# iosam3n register map
Registers are 32-bit, access not given, no defined reset value unless marked. A register's access mark holds for its fields unless they carry their own. Addresses are absolute; registers are grouped by the start of their names; [hi:lo] are bit positions; {n}, {i} and the like mark numbered series; 'fields as' and 'values as' point back to an identical list.

## SCB
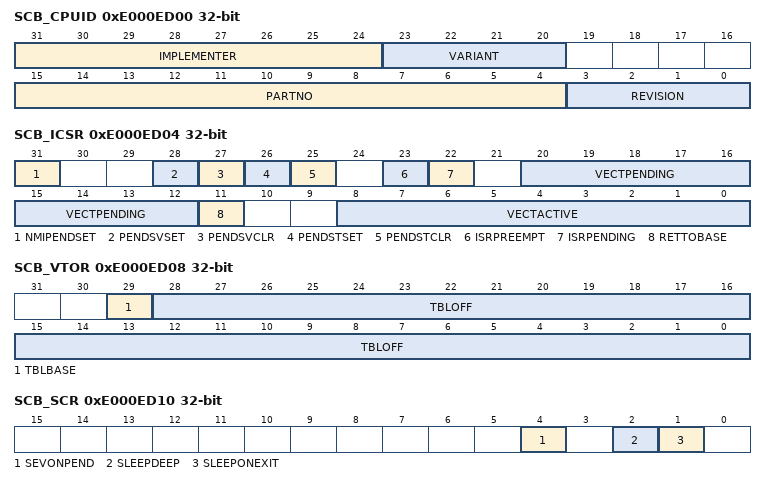
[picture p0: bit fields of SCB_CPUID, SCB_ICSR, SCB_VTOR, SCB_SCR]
0xE000ED00 SCB_CPUID
  [31:24] IMPLEMENTER, [23:20] VARIANT, [15:4] PARTNO, [3:0] REVISION
0xE000ED04 SCB_ICSR
  [31] NMIPENDSET, [28] PENDSVSET, [27] PENDSVCLR, [26] PENDSTSET, [25] PENDSTCLR, [23] ISRPREEMPT, [22] ISRPENDING, [20:12] VECTPENDING, [11] RETTOBASE, [8:0] VECTACTIVE
0xE000ED08 SCB_VTOR
  [29] TBLBASE, [28:0] TBLOFF
0xE000ED0C SCB_AIRCR
  [31:16] VECTKEY, [31:16] VECTKEYSTAT, [15] ENDIANESS, [2] SYSRESETREQ, [1] VECTCLRACTIVE, [0] VECTRESET
0xE000ED10 SCB_SCR
  [4] SEVONPEND, [2] SLEEPDEEP, [1] SLEEPONEXIT
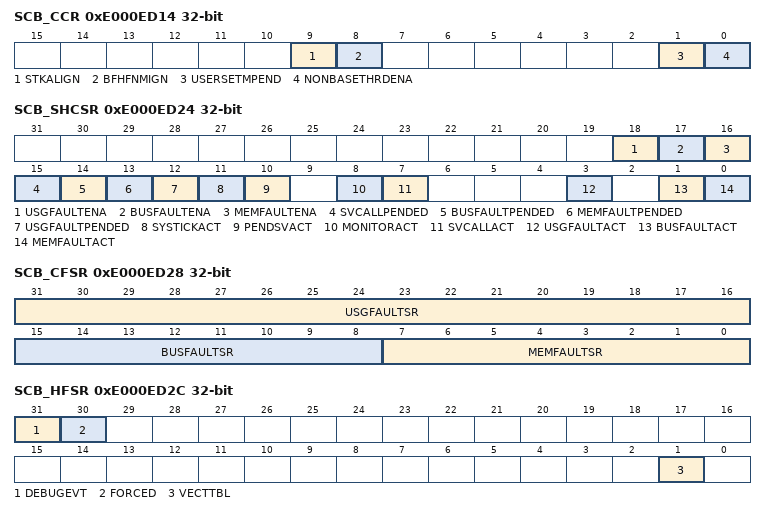
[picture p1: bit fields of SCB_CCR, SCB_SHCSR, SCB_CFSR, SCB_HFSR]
0xE000ED14 SCB_CCR
  [9] STKALIGN, [8] BFHFNMIGN, [1] USERSETMPEND, [0] NONBASETHRDENA
{0xE000ED18+4i} SCB_SHP{i} 8-bit (i=0..11)
0xE000ED24 SCB_SHCSR
  [18] USGFAULTENA, [17] BUSFAULTENA, [16] MEMFAULTENA, [15] SVCALLPENDED, [14] BUSFAULTPENDED, [13] MEMFAULTPENDED, [12] USGFAULTPENDED, [11] SYSTICKACT, [10] PENDSVACT, [8] MONITORACT, [7] SVCALLACT, [3] USGFAULTACT, [1] BUSFAULTACT, [0] MEMFAULTACT
0xE000ED28 SCB_CFSR
  [31:16] USGFAULTSR, [15:8] BUSFAULTSR, [7:0] MEMFAULTSR
0xE000ED2C SCB_HFSR
  [31] DEBUGEVT, [30] FORCED, [1] VECTTBL
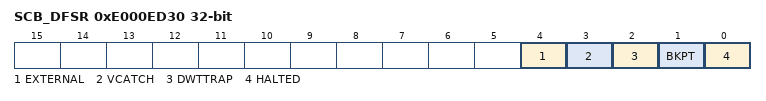
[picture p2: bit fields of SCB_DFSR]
0xE000ED30 SCB_DFSR
  [4] EXTERNAL, [3] VCATCH, [2] DWTTRAP, [1] BKPT, [0] HALTED
0xE000ED34 SCB_MMFAR
0xE000ED38 SCB_BFAR
0xE000ED3C SCB_AFSR
0xE000ED40 SCB_PFR0
0xE000ED44 SCB_PFR1
0xE000ED48 SCB_DFR
0xE000ED4C SCB_ADR
{0xE000ED50+4i} SCB_MMFR{i} (i=0..3)
{0xE000ED60+4i} SCB_ISAR{i} (i=0..4)

## SYSTICK
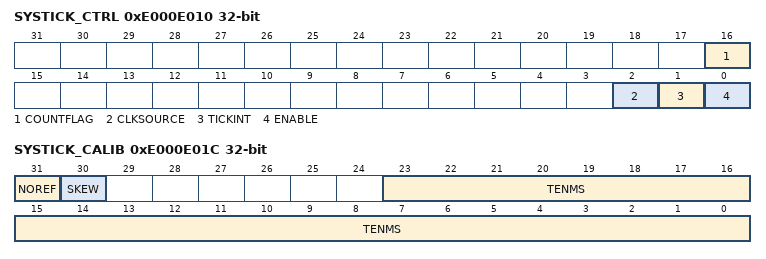
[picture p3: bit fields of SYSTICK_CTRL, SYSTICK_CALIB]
0xE000E010 SYSTICK_CTRL
  [16] COUNTFLAG, [2] CLKSOURCE, [1] TICKINT, [0] ENABLE
0xE000E014 SYSTICK_LOAD
  [23:0] RELOAD
0xE000E018 SYSTICK_VAL
  [23:0] CURRENT
0xE000E01C SYSTICK_CALIB
  [31] NOREF, [30] SKEW, [23:0] TENMS

## INTERRUPTTYPE
0xE000E004 INTERRUPTTYPE_ICTR
  [4:0] INTLINESNUM
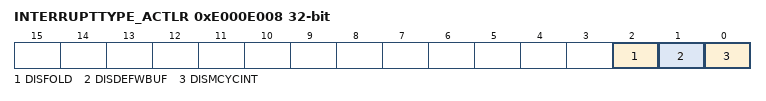
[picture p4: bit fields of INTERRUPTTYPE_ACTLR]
0xE000E008 INTERRUPTTYPE_ACTLR
  [2] DISFOLD, [1] DISDEFWBUF, [0] DISMCYCINT

## COREDEBUG
0xE000EDF0 COREDEBUG_DHCSR
  [31:16] DBGKEY
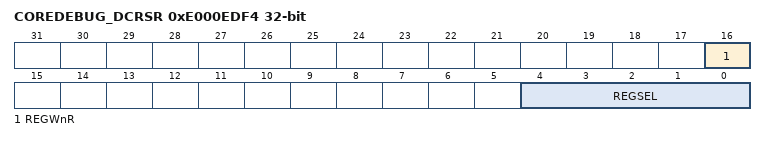
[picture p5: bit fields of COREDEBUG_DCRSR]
0xE000EDF4 COREDEBUG_DCRSR
  [16] REGWnR, [4:0] REGSEL
0xE000EDF8 COREDEBUG_DCRDR
0xE000EDFC COREDEBUG_DEMCR
  [24] TRCENA

## SPI
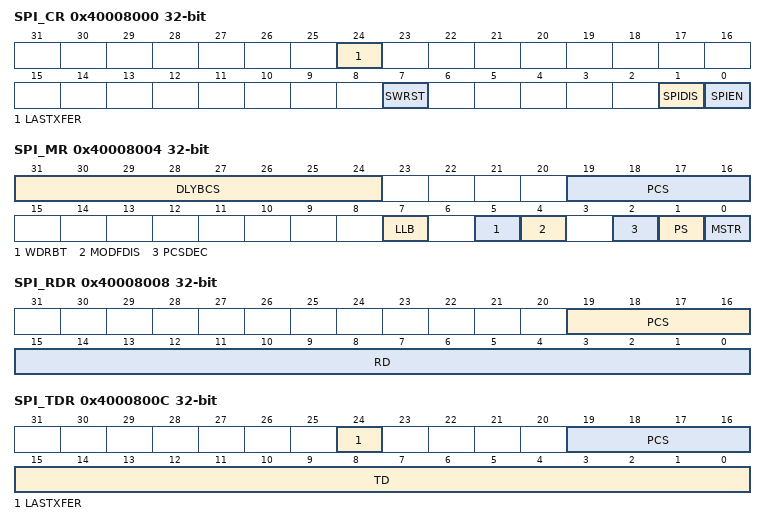
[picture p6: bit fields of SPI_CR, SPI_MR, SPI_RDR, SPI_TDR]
0x40008000 SPI_CR
  [24] LASTXFER, [7] SWRST, [1] SPIDIS, [0] SPIEN
0x40008004 SPI_MR
  [31:24] DLYBCS, [19:16] PCS, [7] LLB, [5] WDRBT, [4] MODFDIS, [2] PCSDEC, [1] PS, [0] MSTR
0x40008008 SPI_RDR
  [19:16] PCS, [15:0] RD
0x4000800C SPI_TDR
  [24] LASTXFER, [19:16] PCS, [15:0] TD
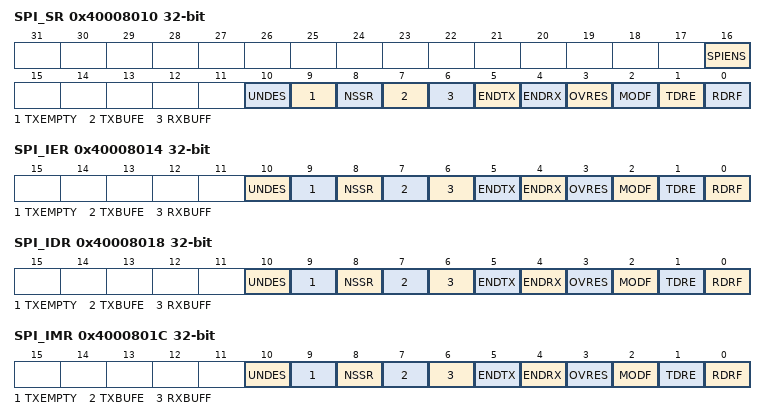
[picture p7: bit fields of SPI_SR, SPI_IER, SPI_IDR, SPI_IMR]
0x40008010 SPI_SR
  [16] SPIENS, [10] UNDES, [9] TXEMPTY, [8] NSSR, [7] TXBUFE, [6] RXBUFF, [5] ENDTX, [4] ENDRX, [3] OVRES, [2] MODF, [1] TDRE, [0] RDRF
0x40008014 SPI_IER
  [10] UNDES, [9] TXEMPTY, [8] NSSR, [7] TXBUFE, [6] RXBUFF, [5] ENDTX, [4] ENDRX, [3] OVRES, [2] MODF, [1] TDRE, [0] RDRF
0x40008018 SPI_IDR
  fields as SPI_IER
0x4000801C SPI_IMR
  fields as SPI_IER
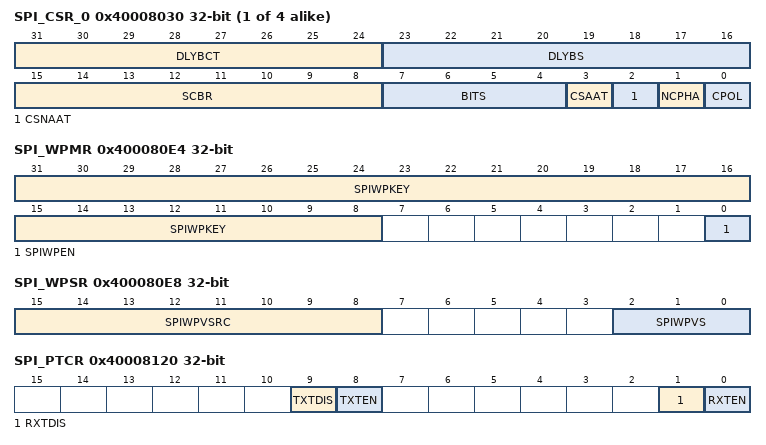
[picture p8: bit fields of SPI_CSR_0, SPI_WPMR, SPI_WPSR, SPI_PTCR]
{0x40008030+4i} SPI_CSR_{i} (i=0..3)
  [31:24] DLYBCT, [23:16] DLYBS, [15:8] SCBR, [7:4] BITS, [3] CSAAT, [2] CSNAAT, [1] NCPHA, [0] CPOL
0x400080E4 SPI_WPMR
  [31:8] SPIWPKEY, [0] SPIWPEN
0x400080E8 SPI_WPSR
  [15:8] SPIWPVSRC, [2:0] SPIWPVS
0x40008100 SPI_RPR
  [31:0] RXPTR
0x40008104 SPI_RCR
  [15:0] RXCTR
0x40008108 SPI_TPR
  [31:0] TXPTR
0x4000810C SPI_TCR
  [15:0] TXCTR
0x40008110 SPI_RNPR
  [31:0] RXNPTR
0x40008114 SPI_RNCR
  [15:0] RXNCTR
0x40008118 SPI_TNPR
  [31:0] TXNPTR
0x4000811C SPI_TNCR
  [15:0] TXNCTR
0x40008120 SPI_PTCR
  [9] TXTDIS, [8] TXTEN, [1] RXTDIS, [0] RXTEN
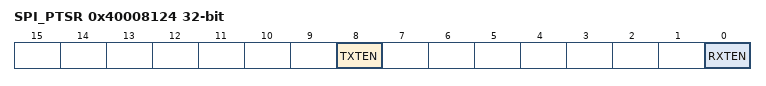
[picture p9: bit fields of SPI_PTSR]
0x40008124 SPI_PTSR
  [8] TXTEN, [0] RXTEN

## TC0
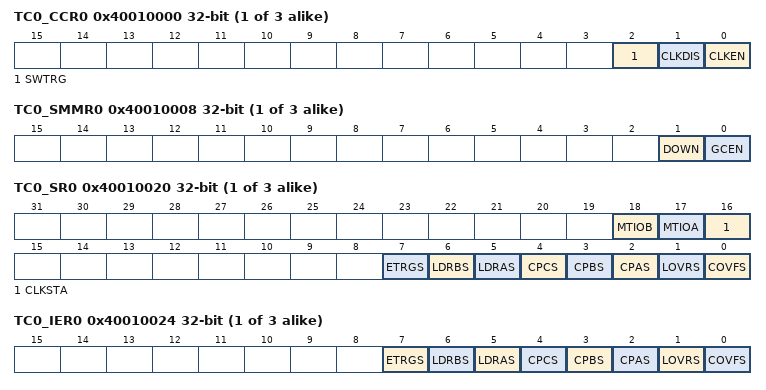
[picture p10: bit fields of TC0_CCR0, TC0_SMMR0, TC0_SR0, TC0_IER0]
{0x40010000+0x40*i} TC0_CCR{i} (i=0..2)
  [2] SWTRG, [1] CLKDIS, [0] CLKEN
{0x40010004+0x40*i} TC0_CMR{i} (i=0..2)
  [31:30] BSWTRG, [29:28] BEEVT, [27:26] BCPC, [25:24] BCPB, [23:22] ASWTRG, [21:20] AEEVT, [19:18] LDRB, [19:18] ACPC, [17:16] LDRA, [17:16] ACPA, [15] WAVE, [14] CPCTRG, [14:13] WAVSEL, [12] ENETRG, [10] ABETRG, [11:10] EEVT, [9:8] ETRGEDG, [9:8] EEVTEDG, [7] LDBDIS, [7] CPCDIS, [6] LDBSTOP, [6] CPCSTOP, [5:4] BURST, [3] CLKI, [2:0] TCCLKS
{0x40010008+0x40*i} TC0_SMMR{i} (i=0..2)
  [1] DOWN, [0] GCEN
{0x40010010+0x40*i} TC0_CV{i} (i=0..2)
  [15:0] CV
{0x40010014+0x40*i} TC0_RA{i} (i=0..2)
  [15:0] RA
{0x40010018+0x40*i} TC0_RB{i} (i=0..2)
  [15:0] RB
{0x4001001C+0x40*i} TC0_RC{i} (i=0..2)
  [15:0] RC
{0x40010020+0x40*i} TC0_SR{i} (i=0..2)
  [18] MTIOB, [17] MTIOA, [16] CLKSTA, [7] ETRGS, [6] LDRBS, [5] LDRAS, [4] CPCS, [3] CPBS, [2] CPAS, [1] LOVRS, [0] COVFS
{0x40010024+0x40*i} TC0_IER{i} (i=0..2)
  [7] ETRGS, [6] LDRBS, [5] LDRAS, [4] CPCS, [3] CPBS, [2] CPAS, [1] LOVRS, [0] COVFS
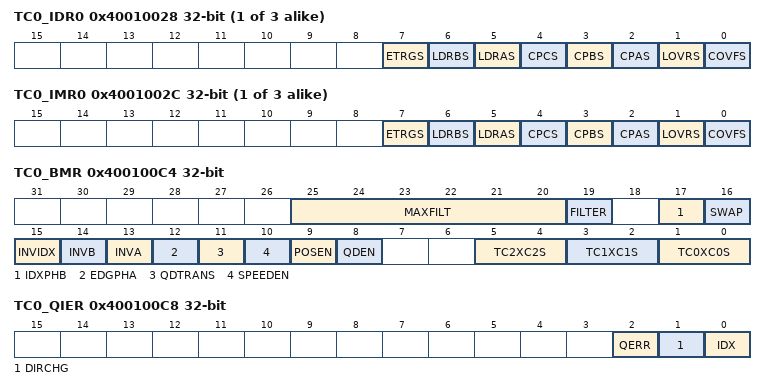
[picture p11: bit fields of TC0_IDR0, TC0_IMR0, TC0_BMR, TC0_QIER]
{0x40010028+0x40*i} TC0_IDR{i} (i=0..2)
  fields as TC0_IER0
{0x4001002C+0x40*i} TC0_IMR{i} (i=0..2)
  fields as TC0_IER0
0x400100C0 TC0_BCR
  [0] SYNC
0x400100C4 TC0_BMR
  [25:20] MAXFILT, [19] FILTER, [17] IDXPHB, [16] SWAP, [15] INVIDX, [14] INVB, [13] INVA, [12] EDGPHA, [11] QDTRANS, [10] SPEEDEN, [9] POSEN, [8] QDEN, [5:4] TC2XC2S, [3:2] TC1XC1S, [1:0] TC0XC0S
0x400100C8 TC0_QIER
  [2] QERR, [1] DIRCHG, [0] IDX
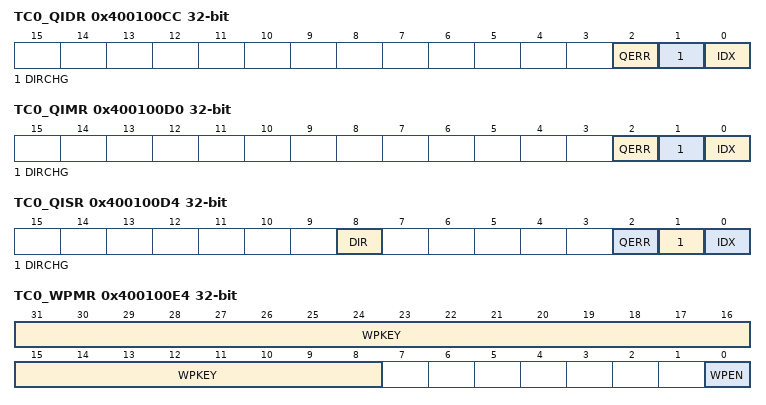
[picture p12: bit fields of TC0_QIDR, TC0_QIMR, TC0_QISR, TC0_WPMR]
0x400100CC TC0_QIDR
  [2] QERR, [1] DIRCHG, [0] IDX
0x400100D0 TC0_QIMR
  [2] QERR, [1] DIRCHG, [0] IDX
0x400100D4 TC0_QISR
  [8] DIR, [2] QERR, [1] DIRCHG, [0] IDX
0x400100E4 TC0_WPMR
  [31:8] WPKEY, [0] WPEN
